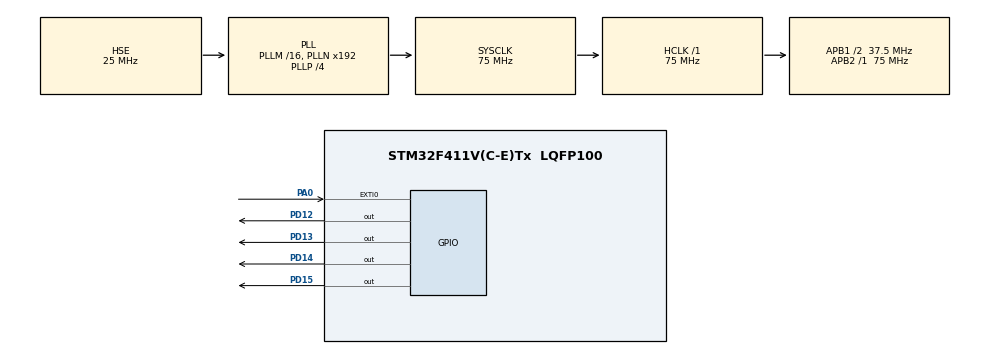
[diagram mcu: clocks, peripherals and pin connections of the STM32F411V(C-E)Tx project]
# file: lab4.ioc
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FREERTOS.Tasks01=defaultTask,24,128,StartDefaultTask,Default,NULL,Static,defaultTaskBuffer,defaultTaskControlBlock;LED1T,8,128,StartLED1T,Default,NULL,Static,LED1TBuffer,LED1TControlBlock;LED2T,8,128,StartLED2T,Default,NULL,Static,LED2TBuffer,LED2TControlBlock
Mcu.Family=STM32F4
Mcu.Name=STM32F411V(C-E)Tx
Mcu.Package=LQFP100
NVIC.EXTI0_IRQn=true\:5\:0\:false\:false\:true\:true\:true\:true\:true
NVIC.PriorityGroup=NVIC_PRIORITYGROUP_4
NVIC.TIM1_UP_TIM10_IRQn=true\:15\:0\:false\:false\:true\:false\:false\:true\:true
NVIC.TimeBase=TIM1_UP_TIM10_IRQn
NVIC.TimeBaseIP=TIM1
PA0-WKUP.Signal=GPXTI0
PA13.Mode=Serial_Wire
PA13.Signal=SYS_JTMS-SWDIO
PA14.Mode=Serial_Wire
PA14.Signal=SYS_JTCK-SWCLK
PC14-OSC32_IN.Mode=LSE-External-Oscillator
PC14-OSC32_IN.Signal=RCC_OSC32_IN
PC15-OSC32_OUT.Mode=LSE-External-Oscillator
PC15-OSC32_OUT.Signal=RCC_OSC32_OUT
PD12.Signal=GPIO_Output
PD13.Signal=GPIO_Output
PD14.Signal=GPIO_Output
PD15.Signal=GPIO_Output
PH0\ -\ OSC_IN.Mode=HSE-External-Oscillator
PH0\ -\ OSC_IN.Signal=RCC_OSC_IN
PH1\ -\ OSC_OUT.Mode=HSE-External-Oscillator
PH1\ -\ OSC_OUT.Signal=RCC_OSC_OUT
ProjectManager.HeapSize=0x200
ProjectManager.StackSize=0x400
ProjectManager.TargetToolchain=STM32CubeIDE
RCC.48MHZClocksFreq_Value=75000000
RCC.AHBFreq_Value=75000000
RCC.APB1CLKDivider=RCC_HCLK_DIV2
RCC.APB1Freq_Value=37500000
RCC.APB1TimFreq_Value=75000000
RCC.APB2Freq_Value=75000000
RCC.APB2TimFreq_Value=75000000
RCC.CortexFreq_Value=75000000
RCC.HCLKFreq_Value=75000000
RCC.HSE_VALUE=25000000
RCC.HSI_VALUE=16000000
RCC.PLLP=RCC_PLLP_DIV4
RCC.PLLSourceVirtual=RCC_PLLSOURCE_HSE
RCC.SYSCLKFreq_VALUE=75000000
RCC.SYSCLKSource=RCC_SYSCLKSOURCE_PLLCLK
RCC.VCOOutputFreq_Value=300000000
VP_FREERTOS_VS_CMSIS_V2.Mode=CMSIS_V2
VP_SYS_VS_tim1.Mode=TIM1
board=custom

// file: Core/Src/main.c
/* USER CODE BEGIN Header */
/**
  ******************************************************************************
  * @file           : main.c
  * @brief          : Main program body
  ******************************************************************************
  * @attention
  *
  * Copyright (c) 2024 STMicroelectronics.
  * All rights reserved.
  *
  * This software is licensed under terms that can be found in the LICENSE file
  * in the root directory of this software component.
  * If no LICENSE file comes with this software, it is provided AS-IS.
  *
  ******************************************************************************
  */
/* USER CODE END Header */
#include "main.h"
#include "cmsis_os.h"

/* USER CODE BEGIN Includes */

#include "string.h"

/* USER CODE END Includes */

typedef StaticTask_t osStaticThreadDef_t;
/* USER CODE BEGIN PTD */

typedef struct {
	char Buf[128];

}QUEUE_t;

/* USER CODE END PTD */

/* Definitions for defaultTask */
osThreadId_t defaultTaskHandle;
uint32_t defaultTaskBuffer[ 128 ];
osStaticThreadDef_t defaultTaskControlBlock;
const osThreadAttr_t defaultTask_attributes = {
  .name = "defaultTask",
  .cb_mem = &defaultTaskControlBlock,
  .cb_size = sizeof(defaultTaskControlBlock),
  .stack_mem = &defaultTaskBuffer[0],
  .stack_size = sizeof(defaultTaskBuffer),
  .priority = (osPriority_t) osPriorityNormal,
};
/* Definitions for LED1T */
osThreadId_t LED1THandle;
uint32_t LED1TBuffer[ 128 ];
osStaticThreadDef_t LED1TControlBlock;
const osThreadAttr_t LED1T_attributes = {
  .name = "LED1T",
  .cb_mem = &LED1TControlBlock,
  .cb_size = sizeof(LED1TControlBlock),
  .stack_mem = &LED1TBuffer[0],
  .stack_size = sizeof(LED1TBuffer),
  .priority = (osPriority_t) osPriorityLow,
};
/* Definitions for LED2T */
osThreadId_t LED2THandle;
uint32_t LED2TBuffer[ 128 ];
osStaticThreadDef_t LED2TControlBlock;
const osThreadAttr_t LED2T_attributes = {
  .name = "LED2T",
  .cb_mem = &LED2TControlBlock,
  .cb_size = sizeof(LED2TControlBlock),
  .stack_mem = &LED2TBuffer[0],
  .stack_size = sizeof(LED2TBuffer),
  .priority = (osPriority_t) osPriorityLow,
};

void SystemClock_Config(void);
static void MX_GPIO_Init(void);
void StartDefaultTask(void *argument);
void StartLED1T(void *argument);
void StartLED2T(void *argument);

/* USER CODE BEGIN PFP */

void HAL_GPIO_EXTI_Callback(uint16_t GPIO_Pin)
{

	HAL_GPIO_TogglePin(GPIOD,GPIO_PIN_14);

}

/* USER CODE END PFP */

int main(void)
{

  /* MCU Configuration--------------------------------------------------------*/

  /* Reset of all peripherals, Initializes the Flash interface and the Systick. */
  HAL_Init();

  /* Configure the system clock */
  SystemClock_Config();

  /* Initialize all configured peripherals */
  MX_GPIO_Init();

  /* Init scheduler */
  osKernelInitialize();

  /* Create the thread(s) */
  /* creation of defaultTask */
  defaultTaskHandle = osThreadNew(StartDefaultTask, NULL, &defaultTask_attributes);

  /* creation of LED1T */
  LED1THandle = osThreadNew(StartLED1T, NULL, &LED1T_attributes);

  /* creation of LED2T */
  LED2THandle = osThreadNew(StartLED2T, NULL, &LED2T_attributes);

  /* Start scheduler */
  osKernelStart();

  /* We should never get here as control is now taken by the scheduler */
  /* Infinite loop */
  while (1)
  {
	  HAL_GPIO_TogglePin(GPIOD,GPIO_PIN_15);
  }
}

void SystemClock_Config(void)
{
  RCC_OscInitTypeDef RCC_OscInitStruct = {0};
  RCC_ClkInitTypeDef RCC_ClkInitStruct = {0};

  /** Configure the main internal regulator output voltage
  */
  __HAL_RCC_PWR_CLK_ENABLE();
  __HAL_PWR_VOLTAGESCALING_CONFIG(PWR_REGULATOR_VOLTAGE_SCALE1);

  /** Initializes the RCC Oscillators according to the specified parameters
  * in the RCC_OscInitTypeDef structure.
  */
  RCC_OscInitStruct.OscillatorType = RCC_OSCILLATORTYPE_HSE;
  RCC_OscInitStruct.HSEState = RCC_HSE_ON;
  RCC_OscInitStruct.PLL.PLLState = RCC_PLL_ON;
  RCC_OscInitStruct.PLL.PLLSource = RCC_PLLSOURCE_HSE;
  RCC_OscInitStruct.PLL.PLLM = 16;
  RCC_OscInitStruct.PLL.PLLN = 192;
  RCC_OscInitStruct.PLL.PLLP = RCC_PLLP_DIV4;
  RCC_OscInitStruct.PLL.PLLQ = 4;
  if (HAL_RCC_OscConfig(&RCC_OscInitStruct) != HAL_OK)
  {
    Error_Handler();
  }

  /** Initializes the CPU, AHB and APB buses clocks
  */
  RCC_ClkInitStruct.ClockType = RCC_CLOCKTYPE_HCLK|RCC_CLOCKTYPE_SYSCLK
                              |RCC_CLOCKTYPE_PCLK1|RCC_CLOCKTYPE_PCLK2;
  RCC_ClkInitStruct.SYSCLKSource = RCC_SYSCLKSOURCE_PLLCLK;
  RCC_ClkInitStruct.AHBCLKDivider = RCC_SYSCLK_DIV1;
  RCC_ClkInitStruct.APB1CLKDivider = RCC_HCLK_DIV2;
  RCC_ClkInitStruct.APB2CLKDivider = RCC_HCLK_DIV1;

  if (HAL_RCC_ClockConfig(&RCC_ClkInitStruct, FLASH_LATENCY_2) != HAL_OK)
  {
    Error_Handler();
  }
}

static void MX_GPIO_Init(void)
{
  GPIO_InitTypeDef GPIO_InitStruct = {0};

  /* GPIO Ports Clock Enable */
  __HAL_RCC_GPIOC_CLK_ENABLE();
  __HAL_RCC_GPIOH_CLK_ENABLE();
  __HAL_RCC_GPIOA_CLK_ENABLE();
  __HAL_RCC_GPIOD_CLK_ENABLE();

  /*Configure GPIO pin Output Level */
  HAL_GPIO_WritePin(GPIOD, GPIO_PIN_12|GPIO_PIN_13|GPIO_PIN_14|GPIO_PIN_15, GPIO_PIN_RESET);

  /*Configure GPIO pin : PA0 */
  GPIO_InitStruct.Pin = GPIO_PIN_0;
  GPIO_InitStruct.Mode = GPIO_MODE_IT_RISING;
  GPIO_InitStruct.Pull = GPIO_NOPULL;
  HAL_GPIO_Init(GPIOA, &GPIO_InitStruct);

  /*Configure GPIO pins : PD12 PD13 PD14 PD15 */
  GPIO_InitStruct.Pin = GPIO_PIN_12|GPIO_PIN_13|GPIO_PIN_14|GPIO_PIN_15;
  GPIO_InitStruct.Mode = GPIO_MODE_OUTPUT_PP;
  GPIO_InitStruct.Pull = GPIO_NOPULL;
  GPIO_InitStruct.Speed = GPIO_SPEED_FREQ_LOW;
  HAL_GPIO_Init(GPIOD, &GPIO_InitStruct);

  /* EXTI interrupt init*/
  HAL_NVIC_SetPriority(EXTI0_IRQn, 5, 0);
  HAL_NVIC_EnableIRQ(EXTI0_IRQn);

}

void StartDefaultTask(void *argument)
{
  for(;;)
  {
    osDelay(1);
  }
}

void StartLED1T(void *argument)
{
  /* USER CODE BEGIN StartLED1T */
  /* Infinite loop */
  for(;;)
  {
	  HAL_GPIO_TogglePin(GPIOD,GPIO_PIN_12);
    osDelay(500);
  }
  /* USER CODE END StartLED1T */
}

void StartLED2T(void *argument)
{
  /* USER CODE BEGIN StartLED2T */
  /* Infinite loop */
  for(;;)
  {
	  HAL_GPIO_TogglePin(GPIOD,GPIO_PIN_13);
    osDelay(500);
  }
  /* USER CODE END StartLED2T */
}

void HAL_TIM_PeriodElapsedCallback(TIM_HandleTypeDef *htim)
{
  if (htim->Instance == TIM1) {
    HAL_IncTick();
  }
}

void Error_Handler(void)
{
  __disable_irq();
  while (1)
  {
  }
}
